# LargeDummyDevice register map
File version: 1.0
Registers are 32-bit, read-write, no defined reset value unless marked. A register's access mark holds for its fields unless they carry their own. Offsets are from the block's base; [hi:lo] are bit positions.

## PERIPHERAL_7
Base 0x40006000
0x04 REG_1 — Register 1
  [34:31] FIELD_1, [35:31] FIELD_5, [34:30] FIELD_10, [31:29] FIELD_2, [28:24] FIELD_3, [23:21] FIELD_17, [23:19] FIELD_9, [23:19] FIELD_16, [21:17] FIELD_14, [10] FIELD_13, [12:8] FIELD_8, [8:7] FIELD_12, [7:4] FIELD_7, [5:3] FIELD_4, [5:1] FIELD_11, [4:1] FIELD_15, [0] FIELD_6
0x08 REG_2 — Register 2
  [29:27] FIELD_3, [26:24] FIELD_6, [26:22] FIELD_2, [23:20] FIELD_1, [14] FIELD_4, [11] FIELD_5
0x0C REG_3 — Register 3
  [29:28] FIELD_7, [20:19] FIELD_2, [18:17] FIELD_3, [15:14] FIELD_6, [11:9] FIELD_8, [5] FIELD_5, [4] FIELD_1, [4] FIELD_4
0x10 REG_4 — Register 4
  [31] FIELD_28, [31:29] FIELD_1, [32:28] FIELD_27, [28:27] FIELD_2, [29:27] FIELD_10, [27] FIELD_11, [29:26] FIELD_4, [26:25] FIELD_22, [23] FIELD_5, [25:21] FIELD_3, [24:20] FIELD_16, [19:18] FIELD_15, [19:17] FIELD_9, [19:15] FIELD_13, [18:15] FIELD_24, [17:13] FIELD_21, [13] FIELD_25, [13:12] FIELD_20, [12:10] FIELD_8, [14:10] FIELD_12, [12:8] FIELD_6, [9:8] FIELD_26, [11:7] FIELD_19, [7:5] FIELD_7, [7:5] FIELD_18, [6:5] FIELD_23, [5:2] FIELD_14, [6:2] FIELD_17
0x14 REG_5 — Register 5
  [34:31] FIELD_5, [33:31] FIELD_17, [29] FIELD_3, [31:29] FIELD_12, [29] FIELD_16, [32:28] FIELD_1, [28] FIELD_4, [29:28] FIELD_15, [32:28] FIELD_26, [29:27] FIELD_2, [28:26] FIELD_11, [24:23] FIELD_13, [23:22] FIELD_8, [26:22] FIELD_19, [24:21] FIELD_25, [20] FIELD_22, [18:17] FIELD_14, [16] FIELD_21, [16:15] FIELD_20, [12:11] FIELD_24, [11:10] FIELD_23, [9] FIELD_18, [6] FIELD_9, [5:4] FIELD_27, [4:2] FIELD_7, [5:2] FIELD_10, [1:0] FIELD_6
0x18 REG_6 — Register 6
  [31:30] FIELD_9, [32:29] FIELD_8, [31:27] FIELD_10, [27:26] FIELD_11, [25:24] FIELD_4, [26:23] FIELD_14, [21] FIELD_5, [18] FIELD_3, [13:12] FIELD_7, [9:7] FIELD_6, [6:4] FIELD_2, [3:2] FIELD_1, [4:0] FIELD_12, [1:0] FIELD_13
0x1C REG_7 — Register 7
  [33:31] FIELD_15, [32:30] FIELD_20, [33:29] FIELD_5, [28:25] FIELD_1, [23] FIELD_11, [22] FIELD_7, [22:21] FIELD_13, [21:19] FIELD_16, [18] FIELD_4, [18:16] FIELD_8, [17:13] FIELD_12, [13:12] FIELD_18, [10] FIELD_17, [11:9] FIELD_10, [8:7] FIELD_9, [7:6] FIELD_2, [10:6] FIELD_3, [10:6] FIELD_14, [9:5] FIELD_19, [4:3] FIELD_6
0x20 REG_8 — Register 8
  [31:28] FIELD_11, [29:27] FIELD_6, [30:26] FIELD_9, [21:19] FIELD_3, [23:19] FIELD_4, [20:18] FIELD_5, [17:16] FIELD_8, [14] FIELD_12, [10:8] FIELD_1, [8:7] FIELD_10, [8:5] FIELD_2, [3:2] FIELD_7
0x24 REG_9 — Register 9
  [30:29] FIELD_18, [32:28] FIELD_4, [31:28] FIELD_9, [29:27] FIELD_13, [28:24] FIELD_22, [27:23] FIELD_11, [25:22] FIELD_12, [23:21] FIELD_8, [20] FIELD_17, [19:18] FIELD_14, [17:15] FIELD_1, [18:15] FIELD_21, [14:11] FIELD_23, [13:10] FIELD_6, [11:10] FIELD_15, [14:10] FIELD_20, [10:8] FIELD_16, [6:5] FIELD_3, [8:5] FIELD_10, [5:4] FIELD_7, [7:3] FIELD_2, [6:2] FIELD_5, [6:2] FIELD_19
0x28 REG_10 — Register 10
  [27:23] FIELD_2, [24:22] FIELD_3, [23:21] FIELD_1, [3:2] FIELD_4
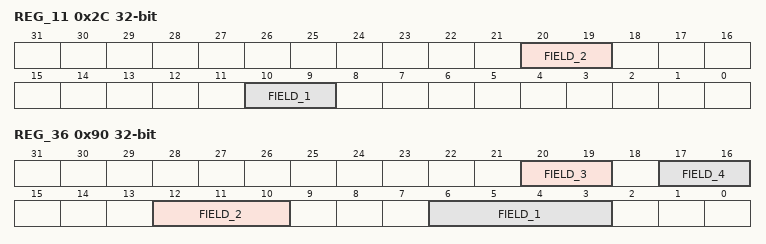
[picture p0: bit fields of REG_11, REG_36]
0x2C REG_11 — Register 11
  [20:19] FIELD_2, [10:9] FIELD_1
0x30 REG_12 — Register 12
  [31] FIELD_5, [32:30] FIELD_14, [33:29] FIELD_25, [29:25] FIELD_7, [25:24] FIELD_4, [25:24] FIELD_18, [25:21] FIELD_20, [22:20] FIELD_2, [24:20] FIELD_3, [24:20] FIELD_21, [19:17] FIELD_16, [20:16] FIELD_24, [19:15] FIELD_19, [18:14] FIELD_22, [15:13] FIELD_23, [14:13] FIELD_26, [16:12] FIELD_1, [12:11] FIELD_11, [14:11] FIELD_13, [14:11] FIELD_27, [14:10] FIELD_10, [7] FIELD_6, [8:6] FIELD_15, [6:5] FIELD_8, [5:2] FIELD_12, [1:0] FIELD_9, [0] FIELD_17
0x34 REG_13 — Register 13
  [29:27] FIELD_1, [30:27] FIELD_4, [26] FIELD_8, [27:25] FIELD_5, [27:23] FIELD_9, [27:23] FIELD_10, [20:19] FIELD_6, [14] FIELD_2, [13:12] FIELD_7, [6:5] FIELD_3
0x38 REG_14 — Register 14
  [32:31] FIELD_18, [32:31] FIELD_19, [35:31] FIELD_25, [30:29] FIELD_3, [28:27] FIELD_15, [27] FIELD_17, [28:27] FIELD_22, [28:25] FIELD_20, [26:24] FIELD_5, [25:23] FIELD_23, [24:23] FIELD_30, [25:21] FIELD_12, [22:21] FIELD_28, [22:20] FIELD_16, [21:18] FIELD_8, [21:17] FIELD_2, [13] FIELD_7, [16:13] FIELD_24, [15:12] FIELD_6, [13:12] FIELD_9, [15:11] FIELD_4, [12:11] FIELD_26, [15:11] FIELD_29, [10] FIELD_13, [8] FIELD_1, [9:7] FIELD_10, [8:5] FIELD_21, [7:5] FIELD_27, [5:3] FIELD_11, [4:2] FIELD_14
0x3C REG_15 — Register 15
  [30] FIELD_10, [28:26] FIELD_8, [25] FIELD_2, [25:23] FIELD_3, [11] FIELD_9, [12:9] FIELD_5, [10:8] FIELD_7, [11:7] FIELD_1, [8:4] FIELD_4, [3] FIELD_6
0x40 REG_16 — Register 16
  [34:31] FIELD_6, [31] FIELD_13, [32:30] FIELD_9, [30] FIELD_22, [30:27] FIELD_8, [30:26] FIELD_4, [26] FIELD_19, [25:23] FIELD_15, [23:22] FIELD_21, [21:19] FIELD_11, [17:14] FIELD_17, [15:12] FIELD_5, [13:11] FIELD_14, [11:9] FIELD_10, [10:8] FIELD_2, [12:8] FIELD_3, [12:8] FIELD_12, [9:7] FIELD_1, [5:3] FIELD_7, [4:3] FIELD_18, [1] FIELD_23, [4:0] FIELD_16, [1:0] FIELD_20
0x44 REG_17 — Register 17
  [27:26] FIELD_5, [20:19] FIELD_8, [20:17] FIELD_2, [15:14] FIELD_6, [12:11] FIELD_4, [13:11] FIELD_7, [11:10] FIELD_1, [11:10] FIELD_3, [10:6] FIELD_9
0x48 REG_18 — Register 18
  [28] FIELD_13, [30:28] FIELD_16, [27:24] FIELD_14, [23:21] FIELD_6, [22:20] FIELD_3, [23:19] FIELD_7, [18] FIELD_1, [18:17] FIELD_17, [16:15] FIELD_2, [15:12] FIELD_12, [11:8] FIELD_11, [6] FIELD_4, [9:6] FIELD_8, [5] FIELD_9, [7:3] FIELD_10, [2] FIELD_15, [2:0] FIELD_5
0x4C REG_19 — Register 19
  [33:31] FIELD_8, [32:31] FIELD_13, [33:29] FIELD_6, [33:29] FIELD_15, [31:27] FIELD_14, [29:26] FIELD_12, [28:25] FIELD_20, [20:18] FIELD_7, [18:16] FIELD_9, [16] FIELD_10, [19:15] FIELD_16, [16:15] FIELD_17, [16:14] FIELD_21, [14:11] FIELD_11, [10] FIELD_4, [11:9] FIELD_2, [9:6] FIELD_5, [6] FIELD_18, [4:3] FIELD_3, [3] FIELD_22, [2:0] FIELD_1, [3:0] FIELD_19
0x50 REG_20 — Register 20
  [32:31] FIELD_11, [33:29] FIELD_2, [28:26] FIELD_18, [29:25] FIELD_6, [26:22] FIELD_20, [22:21] FIELD_4, [24:21] FIELD_13, [20] FIELD_8, [22:20] FIELD_21, [21:19] FIELD_10, [19] FIELD_12, [19] FIELD_19, [19:15] FIELD_1, [18:15] FIELD_3, [13:11] FIELD_9, [13:9] FIELD_17, [10:6] FIELD_14, [7:4] FIELD_15, [3:2] FIELD_5, [3:2] FIELD_16, [0] FIELD_7
0x54 REG_21 — Register 21
  [31] FIELD_6, [32:31] FIELD_7, [31] FIELD_8, [29] FIELD_13, [30:29] FIELD_19, [28:26] FIELD_17, [24] FIELD_11, [23:21] FIELD_1, [21:17] FIELD_5, [17:13] FIELD_9, [12] FIELD_3, [14:12] FIELD_4, [10:7] FIELD_10, [9:7] FIELD_12, [9:7] FIELD_15, [8:6] FIELD_16, [8:4] FIELD_14, [4:3] FIELD_18, [3:2] FIELD_2, [3:1] FIELD_20
0x58 REG_22 — Register 22
  [33:30] FIELD_8, [30:29] FIELD_6, [31:28] FIELD_7, [31:28] FIELD_16, [28] FIELD_24, [29:26] FIELD_19, [29:25] FIELD_1, [25] FIELD_23, [26:24] FIELD_17, [26:22] FIELD_22, [23:21] FIELD_2, [25:21] FIELD_10, [21:19] FIELD_20, [17:16] FIELD_26, [17:14] FIELD_15, [13] FIELD_4, [12:11] FIELD_14, [13:9] FIELD_11, [9] FIELD_21, [11:8] FIELD_13, [8:7] FIELD_5, [2] FIELD_3, [5:1] FIELD_12, [5:1] FIELD_18, [4:1] FIELD_25, [2:0] FIELD_9
0x5C REG_23 — Register 23
  [34:31] FIELD_2, [32:30] FIELD_7, [33:30] FIELD_15, [29] FIELD_16, [25:24] FIELD_9, [27:24] FIELD_12, [21] FIELD_8, [21:18] FIELD_6, [17] FIELD_4, [20:16] FIELD_13, [15] FIELD_17, [16:14] FIELD_11, [13:12] FIELD_5, [15:11] FIELD_3, [9:7] FIELD_14, [5:3] FIELD_1, [6:3] FIELD_10
0x60 REG_24 — Register 24
  [32:31] FIELD_17, [35:31] FIELD_19, [32:30] FIELD_21, [31:30] FIELD_29, [30:29] FIELD_10, [31:28] FIELD_4, [29:28] FIELD_9, [32:28] FIELD_24, [29:28] FIELD_27, [26:25] FIELD_7, [22] FIELD_11, [23:22] FIELD_20, [24:20] FIELD_15, [23:19] FIELD_6, [21:18] FIELD_23, [19:17] FIELD_25, [20:16] FIELD_16, [19:15] FIELD_5, [15:14] FIELD_13, [15:13] FIELD_26, [15:12] FIELD_2, [11] FIELD_14, [11:7] FIELD_1, [9:6] FIELD_8, [7:6] FIELD_28, [8:5] FIELD_18, [6:3] FIELD_3, [3:1] FIELD_22, [4:0] FIELD_12
0x64 REG_25 — Register 25
  [34:30] FIELD_17, [30] FIELD_18, [29] FIELD_4, [29:28] FIELD_7, [31:27] FIELD_14, [29:25] FIELD_6, [23:20] FIELD_12, [20:19] FIELD_3, [20:19] FIELD_13, [20:16] FIELD_2, [15] FIELD_1, [14:12] FIELD_16, [11:9] FIELD_8, [7:6] FIELD_9, [6] FIELD_15, [3] FIELD_5, [6:3] FIELD_20, [6:2] FIELD_19, [4:1] FIELD_10, [1:0] FIELD_11
0x68 REG_26 — Register 26
  [30] FIELD_12, [30] FIELD_14, [31:30] FIELD_19, [30:28] FIELD_10, [27:26] FIELD_7, [29:25] FIELD_9, [25] FIELD_18, [25:24] FIELD_30, [27:23] FIELD_8, [26:22] FIELD_1, [24:21] FIELD_13, [21] FIELD_15, [23:21] FIELD_20, [22:20] FIELD_25, [22:20] FIELD_28, [21:17] FIELD_17, [17] FIELD_22, [20:16] FIELD_2, [13] FIELD_23, [15:13] FIELD_24, [16:12] FIELD_29, [15:11] FIELD_6, [12:11] FIELD_11, [12:11] FIELD_21, [10:9] FIELD_27, [10:8] FIELD_5, [7:6] FIELD_16, [5] FIELD_26, [7:3] FIELD_3, [5:3] FIELD_4
0x6C REG_27 — Register 27
  [34:30] FIELD_4, [32:30] FIELD_9, [29:28] FIELD_6, [23:22] FIELD_10, [23:21] FIELD_5, [21:20] FIELD_1, [16:14] FIELD_7, [11:9] FIELD_3, [5:4] FIELD_11, [8:4] FIELD_12, [4:3] FIELD_8, [1:0] FIELD_2
0x70 REG_28 — Register 28
  [34:30] FIELD_2, [34:30] FIELD_3, [31:27] FIELD_4, [27:23] FIELD_15, [26:22] FIELD_6, [25:21] FIELD_9, [24:20] FIELD_11, [14] FIELD_1, [17:14] FIELD_5, [13] FIELD_13, [11:10] FIELD_8, [10:8] FIELD_10, [3:1] FIELD_7, [3:1] FIELD_12, [0] FIELD_14
0x74 REG_29 — Register 29
  [32:31] FIELD_1, [30] FIELD_2, [28:26] FIELD_5, [8:7] FIELD_4, [8:5] FIELD_3
0x78 REG_30 — Register 30
  [30:29] FIELD_12, [28] FIELD_8, [29:28] FIELD_9, [28:27] FIELD_17, [26:23] FIELD_14, [26:23] FIELD_20, [22] FIELD_7, [25:22] FIELD_10, [23:20] FIELD_13, [21:19] FIELD_5, [19:17] FIELD_18, [18:16] FIELD_6, [13] FIELD_2, [8] FIELD_3, [7:6] FIELD_1, [10:6] FIELD_11, [7:5] FIELD_4, [7:5] FIELD_19, [4:3] FIELD_15, [4:0] FIELD_16
0x7C REG_31 — Register 31
  [34:31] FIELD_14, [33:31] FIELD_25, [34:30] FIELD_6, [31:28] FIELD_2, [32:28] FIELD_15, [28:26] FIELD_18, [28:26] FIELD_19, [28:26] FIELD_22, [28:25] FIELD_4, [28:25] FIELD_23, [24] FIELD_13, [22] FIELD_10, [24:22] FIELD_11, [26:22] FIELD_20, [23:22] FIELD_21, [21:20] FIELD_1, [24:20] FIELD_3, [22:20] FIELD_12, [23:19] FIELD_5, [16:13] FIELD_16, [15:12] FIELD_9, [9:6] FIELD_8, [10:6] FIELD_17, [7:5] FIELD_7, [8:4] FIELD_24
0x80 REG_32 — Register 32
  [32:30] FIELD_10, [26:25] FIELD_4, [25:23] FIELD_9, [24:22] FIELD_3, [11:10] FIELD_7, [9] FIELD_1, [12:8] FIELD_11, [6] FIELD_2, [8:6] FIELD_5, [5:4] FIELD_6, [0] FIELD_8
0x84 REG_33 — Register 33
  [33:31] FIELD_11, [31] FIELD_18, [32:31] FIELD_21, [32:31] FIELD_30, [32:29] FIELD_1, [29] FIELD_22, [32:28] FIELD_15, [29:25] FIELD_4, [26:23] FIELD_23, [23:21] FIELD_28, [22:19] FIELD_16, [20:18] FIELD_3, [20:18] FIELD_12, [20:18] FIELD_14, [17] FIELD_5, [21:17] FIELD_29, [18:15] FIELD_31, [12] FIELD_17, [12] FIELD_19, [13:9] FIELD_6, [10:9] FIELD_26, [8] FIELD_2, [9:8] FIELD_20, [9:5] FIELD_7, [7:3] FIELD_10, [5:3] FIELD_13, [5:3] FIELD_27, [6:2] FIELD_8, [4:2] FIELD_9, [3:2] FIELD_25, [2:0] FIELD_24
0x88 REG_34 — Register 34
  [31:30] FIELD_2, [30] FIELD_11, [32:28] FIELD_17, [29:27] FIELD_14, [27:26] FIELD_4, [26] FIELD_13, [24] FIELD_7, [28:24] FIELD_9, [24:23] FIELD_1, [23:21] FIELD_10, [22:19] FIELD_8, [21:18] FIELD_15, [17:14] FIELD_16, [17:13] FIELD_6, [9:7] FIELD_3, [2] FIELD_12, [4:0] FIELD_5
0x8C REG_35 — Register 35
  [30] FIELD_3, [34:30] FIELD_5, [30:29] FIELD_9, [24:23] FIELD_12, [23:22] FIELD_6, [25:22] FIELD_11, [21:19] FIELD_14, [21:17] FIELD_1, [16:14] FIELD_2, [13] FIELD_4, [10:9] FIELD_7, [13:9] FIELD_13, [9:5] FIELD_10, [4] FIELD_8
0x90 REG_36 — Register 36
  [20:19] FIELD_3, [17:16] FIELD_4, [12:10] FIELD_2, [6:3] FIELD_1
0x94 REG_37 — Register 37
  [27:24] FIELD_1, [19:15] FIELD_3, [15:12] FIELD_2, [3] FIELD_5, [3:0] FIELD_4
0x98 REG_38 — Register 38
  [31] FIELD_8, [29:28] FIELD_1, [32:28] FIELD_9, [30:27] FIELD_14, [27:26] FIELD_4, [26:25] FIELD_16, [25:24] FIELD_7, [23:20] FIELD_12, [19] FIELD_17, [20:18] FIELD_15, [21:17] FIELD_2, [14:13] FIELD_10, [14:12] FIELD_5, [13:10] FIELD_11, [12:9] FIELD_6, [8:6] FIELD_13, [5:4] FIELD_3
0x9C REG_39 — Register 39
  [28:26] FIELD_3, [28:26] FIELD_5, [27:25] FIELD_2, [28:24] FIELD_1, [7:3] FIELD_4, [3:2] FIELD_6
